# AST1060 register map
File version: 1.0
CPU: CM4 r0p1, little endian, MPU, FPU, 4 interrupt priority bits, 256 interrupts
Registers are 32-bit, read-write, reset 0x0 unless marked. A register's access mark holds for its fields unless they carry their own. Offsets are from the block's base; [hi:lo] are bit positions.

## gpio
Base 0x7E780000
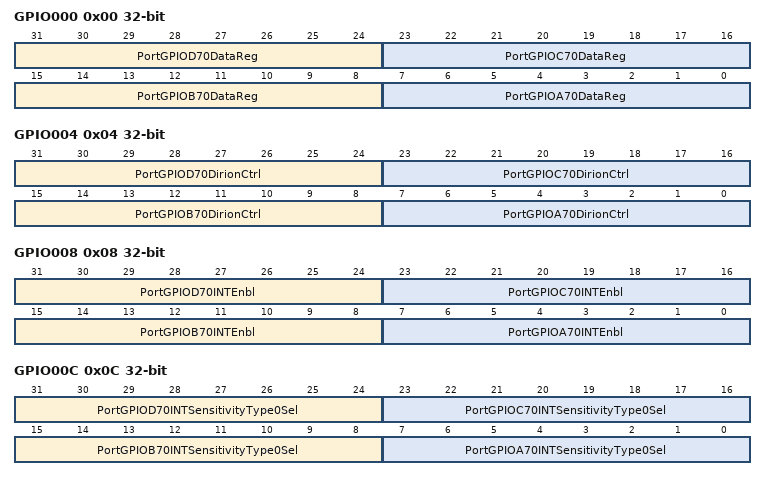
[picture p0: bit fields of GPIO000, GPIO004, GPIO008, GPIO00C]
0x00 GPIO000 — GPIO\_A/B/C/D Data Value Register
  [31:24] PortGPIOD70DataReg — Port GPIOD[7:0] data register
  [23:16] PortGPIOC70DataReg — Port GPIOC[7:0] data register
  [15:8] PortGPIOB70DataReg — Port GPIOB[7:0] data register
  [7:0] PortGPIOA70DataReg — Port GPIOA[7:0] data register
0x04 GPIO004 — GPIO\_A/B/C/D Direction Register
  [31:24] PortGPIOD70DirionCtrl — Port GPIOD[7:0] direction control
  [23:16] PortGPIOC70DirionCtrl — Port GPIOC[7:0] direction control
  [15:8] PortGPIOB70DirionCtrl — Port GPIOB[7:0] direction control
  [7:0] PortGPIOA70DirionCtrl — Port GPIOA[7:0] direction control
0x08 GPIO008 — GPIO\_A/B/C/D Interrupt Enable Register
  [31:24] PortGPIOD70INTEnbl — Port GPIOD[7:0] interrupt enable
  [23:16] PortGPIOC70INTEnbl — Port GPIOC[7:0] interrupt enable
  [15:8] PortGPIOB70INTEnbl — Port GPIOB[7:0] interrupt enable
  [7:0] PortGPIOA70INTEnbl — Port GPIOA[7:0] interrupt enable
0x0C GPIO00C — GPIO\_A/B/C/D Interrupt Sensitivity Type 0 Register
  [31:24] PortGPIOD70INTSensitivityType0Sel — Port GPIOD[7:0] interrupt sensitivity type 0 selection
  [23:16] PortGPIOC70INTSensitivityType0Sel — Port GPIOC[7:0] interrupt sensitivity type 0 selection
  [15:8] PortGPIOB70INTSensitivityType0Sel — Port GPIOB[7:0] interrupt sensitivity type 0 selection
  [7:0] PortGPIOA70INTSensitivityType0Sel — Port GPIOA[7:0] interrupt sensitivity type 0 selection
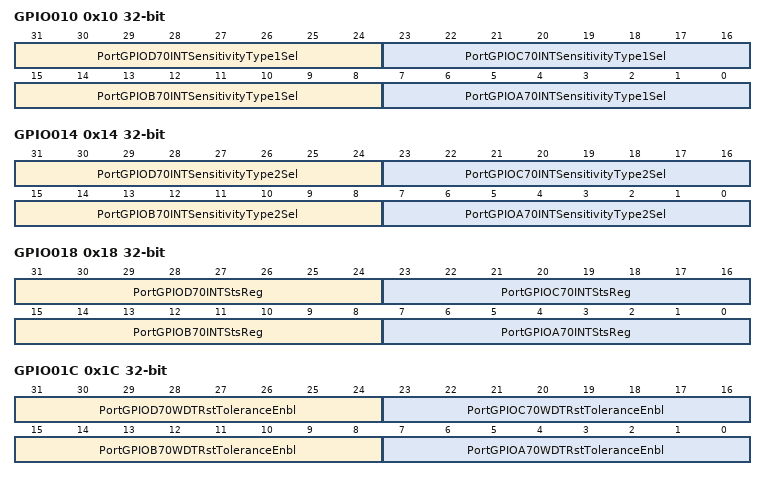
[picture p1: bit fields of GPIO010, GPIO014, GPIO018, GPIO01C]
0x10 GPIO010 — GPIO\_A/B/C/D Interrupt Sensitivity Type 1 Register
  [31:24] PortGPIOD70INTSensitivityType1Sel — Port GPIOD[7:0] interrupt sensitivity type 1 selection
  [23:16] PortGPIOC70INTSensitivityType1Sel — Port GPIOC[7:0] interrupt sensitivity type 1 selection
  [15:8] PortGPIOB70INTSensitivityType1Sel — Port GPIOB[7:0] interrupt sensitivity type 1 selection
  [7:0] PortGPIOA70INTSensitivityType1Sel — Port GPIOA[7:0] interrupt sensitivity type 1 selection
0x14 GPIO014 — GPIO\_A/B/C/D Interrupt Sensitivity Type 2 Register
  [31:24] PortGPIOD70INTSensitivityType2Sel — Port GPIOD[7:0] interrupt sensitivity type 2 selection
  [23:16] PortGPIOC70INTSensitivityType2Sel — Port GPIOC[7:0] interrupt sensitivity type 2 selection
  [15:8] PortGPIOB70INTSensitivityType2Sel — Port GPIOB[7:0] interrupt sensitivity type 2 selection
  [7:0] PortGPIOA70INTSensitivityType2Sel — Port GPIOA[7:0] interrupt sensitivity type 2 selection
0x18 GPIO018 — GPIO\_A/B/C/D Interrupt Status Register
  [31:24] PortGPIOD70INTStsReg — Port GPIOD[7:0] interrupt status register
  [23:16] PortGPIOC70INTStsReg — Port GPIOC[7:0] interrupt status register
  [15:8] PortGPIOB70INTStsReg — Port GPIOB[7:0] interrupt status register
  [7:0] PortGPIOA70INTStsReg — Port GPIOA[7:0] interrupt status register
0x1C GPIO01C — GPIO\_A/B/C/D Reset Tolerant Register
  [31:24] PortGPIOD70WDTRstToleranceEnbl — Port GPIOD[7:0] WDT reset tolerance enable
  [23:16] PortGPIOC70WDTRstToleranceEnbl — Port GPIOC[7:0] WDT reset tolerance enable
  [15:8] PortGPIOB70WDTRstToleranceEnbl — Port GPIOB[7:0] WDT reset tolerance enable
  [7:0] PortGPIOA70WDTRstToleranceEnbl — Port GPIOA[7:0] WDT reset tolerance enable
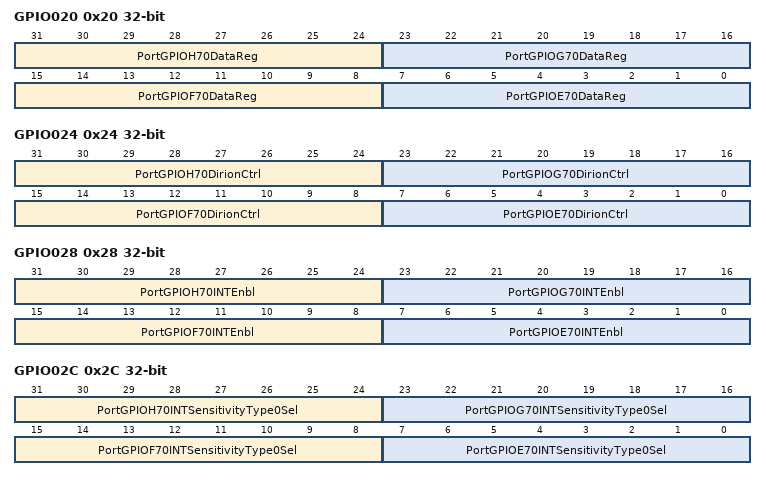
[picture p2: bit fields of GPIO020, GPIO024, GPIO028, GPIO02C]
0x20 GPIO020 — GPIO\_E/F/G/H Data Value Register
  [31:24] PortGPIOH70DataReg — Port GPIOH[7:0] data register
  [23:16] PortGPIOG70DataReg — Port GPIOG[7:0] data register
  [15:8] PortGPIOF70DataReg — Port GPIOF[7:0] data register
  [7:0] PortGPIOE70DataReg — Port GPIOE[7:0] data register
0x24 GPIO024 — GPIO\_E/F/G/H Direction Register
  [31:24] PortGPIOH70DirionCtrl — Port GPIOH[7:0] direction control
  [23:16] PortGPIOG70DirionCtrl — Port GPIOG[7:0] direction control
  [15:8] PortGPIOF70DirionCtrl — Port GPIOF[7:0] direction control
  [7:0] PortGPIOE70DirionCtrl — Port GPIOE[7:0] direction control
0x28 GPIO028 — GPIO\_E/F/G/H Interrupt Enable Register
  [31:24] PortGPIOH70INTEnbl — Port GPIOH[7:0] interrupt enable
  [23:16] PortGPIOG70INTEnbl — Port GPIOG[7:0] interrupt enable
  [15:8] PortGPIOF70INTEnbl — Port GPIOF[7:0] interrupt enable
  [7:0] PortGPIOE70INTEnbl — Port GPIOE[7:0] interrupt enable
0x2C GPIO02C — GPIO\_E/F/G/H Interrupt Sensitivity Type 0 Register
  [31:24] PortGPIOH70INTSensitivityType0Sel — Port GPIOH[7:0] interrupt sensitivity type 0 selection
  [23:16] PortGPIOG70INTSensitivityType0Sel — Port GPIOG[7:0] interrupt sensitivity type 0 selection
  [15:8] PortGPIOF70INTSensitivityType0Sel — Port GPIOF[7:0] interrupt sensitivity type 0 selection
  [7:0] PortGPIOE70INTSensitivityType0Sel — Port GPIOE[7:0] interrupt sensitivity type 0 selection
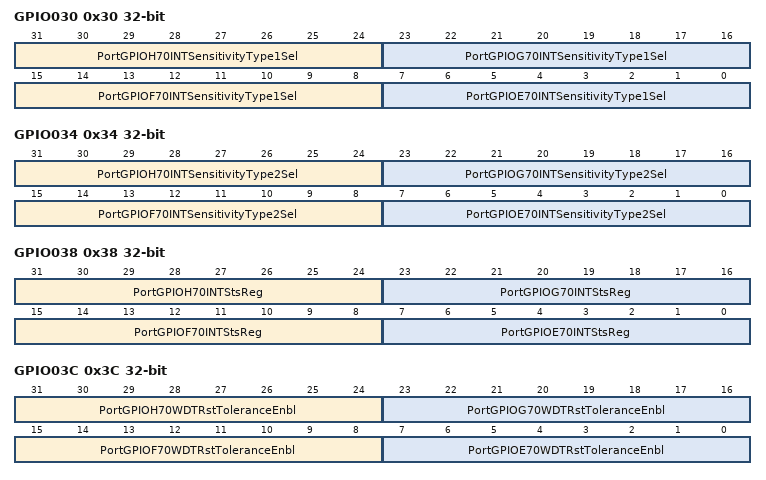
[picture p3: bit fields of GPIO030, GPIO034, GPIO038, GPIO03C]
0x30 GPIO030 — GPIO\_E/F/G/H Interrupt Sensitivity Type 1 Register
  [31:24] PortGPIOH70INTSensitivityType1Sel — Port GPIOH[7:0] interrupt sensitivity type 1 selection
  [23:16] PortGPIOG70INTSensitivityType1Sel — Port GPIOG[7:0] interrupt sensitivity type 1 selection
  [15:8] PortGPIOF70INTSensitivityType1Sel — Port GPIOF[7:0] interrupt sensitivity type 1 selection
  [7:0] PortGPIOE70INTSensitivityType1Sel — Port GPIOE[7:0] interrupt sensitivity type 1 selection
0x34 GPIO034 — GPIO\_E/F/G/H Interrupt Sensitivity Type 2 Register
  [31:24] PortGPIOH70INTSensitivityType2Sel — Port GPIOH[7:0] interrupt sensitivity type 2 selection
  [23:16] PortGPIOG70INTSensitivityType2Sel — Port GPIOG[7:0] interrupt sensitivity type 2 selection
  [15:8] PortGPIOF70INTSensitivityType2Sel — Port GPIOF[7:0] interrupt sensitivity type 2 selection
  [7:0] PortGPIOE70INTSensitivityType2Sel — Port GPIOE[7:0] interrupt sensitivity type 2 selection
0x38 GPIO038 — GPIO\_E/F/G/H Interrupt Status Register
  [31:24] PortGPIOH70INTStsReg — Port GPIOH[7:0] interrupt status register
  [23:16] PortGPIOG70INTStsReg — Port GPIOG[7:0] interrupt status register
  [15:8] PortGPIOF70INTStsReg — Port GPIOF[7:0] interrupt status register
  [7:0] PortGPIOE70INTStsReg — Port GPIOE[7:0] interrupt status register
0x3C GPIO03C — GPIO\_E/F/G/H Reset Tolerant Register
  [31:24] PortGPIOH70WDTRstToleranceEnbl — Port GPIOH[7:0] WDT reset tolerance enable
  [23:16] PortGPIOG70WDTRstToleranceEnbl — Port GPIOG[7:0] WDT reset tolerance enable
  [15:8] PortGPIOF70WDTRstToleranceEnbl — Port GPIOF[7:0] WDT reset tolerance enable
  [7:0] PortGPIOE70WDTRstToleranceEnbl — Port GPIOE[7:0] WDT reset tolerance enable
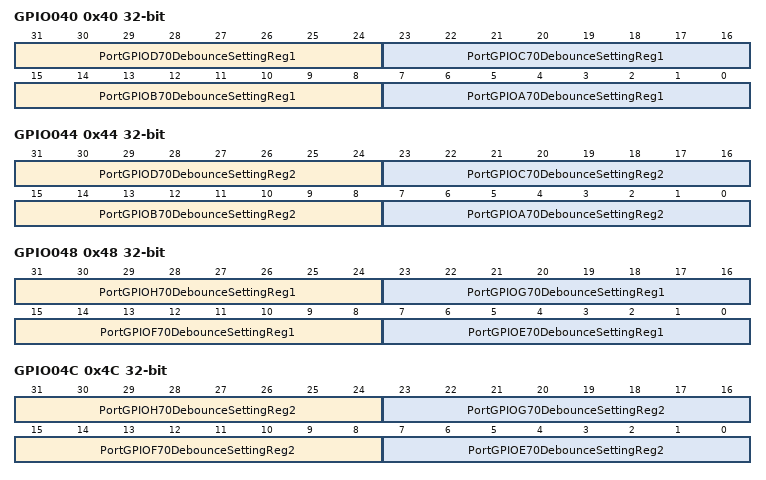
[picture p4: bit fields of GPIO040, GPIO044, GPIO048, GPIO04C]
0x40 GPIO040 — GPIO\_A/B/C/D Debounce Setting Register \#1
  [31:24] PortGPIOD70DebounceSettingReg1 — Port GPIOD[7:0] debounce setting register #1
  [23:16] PortGPIOC70DebounceSettingReg1 — Port GPIOC[7:0] debounce setting register #1
  [15:8] PortGPIOB70DebounceSettingReg1 — Port GPIOB[7:0] debounce setting register #1
  [7:0] PortGPIOA70DebounceSettingReg1 — Port GPIOA[7:0] debounce setting register #1
0x44 GPIO044 — GPIO\_A/B/C/D Debounce Setting Register \#2
  [31:24] PortGPIOD70DebounceSettingReg2 — Port GPIOD[7:0] debounce setting register #2
  [23:16] PortGPIOC70DebounceSettingReg2 — Port GPIOC[7:0] debounce setting register #2
  [15:8] PortGPIOB70DebounceSettingReg2 — Port GPIOB[7:0] debounce setting register #2
  [7:0] PortGPIOA70DebounceSettingReg2 — Port GPIOA[7:0] debounce setting register #2
0x48 GPIO048 — GPIO\_E/F/G/H Debounce Setting Register \#1
  [31:24] PortGPIOH70DebounceSettingReg1 — Port GPIOH[7:0] debounce setting register #1
  [23:16] PortGPIOG70DebounceSettingReg1 — Port GPIOG[7:0] debounce setting register #1
  [15:8] PortGPIOF70DebounceSettingReg1 — Port GPIOF[7:0] debounce setting register #1
  [7:0] PortGPIOE70DebounceSettingReg1 — Port GPIOE[7:0] debounce setting register #1
0x4C GPIO04C — GPIO\_E/F/G/H Debounce Setting Register \#2
  [31:24] PortGPIOH70DebounceSettingReg2 — Port GPIOH[7:0] debounce setting register #2
  [23:16] PortGPIOG70DebounceSettingReg2 — Port GPIOG[7:0] debounce setting register #2
  [15:8] PortGPIOF70DebounceSettingReg2 — Port GPIOF[7:0] debounce setting register #2
  [7:0] PortGPIOE70DebounceSettingReg2 — Port GPIOE[7:0] debounce setting register #2
0x50 GPIO050 — Debounce Timer Setting Register \#1
  [23:0] DebounceTimerValue
0x54 GPIO054 — Debounce Timer Setting Register \#2
  [23:0] DebounceTimerValue1 — Debounce Timer Value
0x58 GPIO058 — Debounce Timer Setting Register \#3
  [23:0] DebounceTimerValue2 — Debounce Timer Value
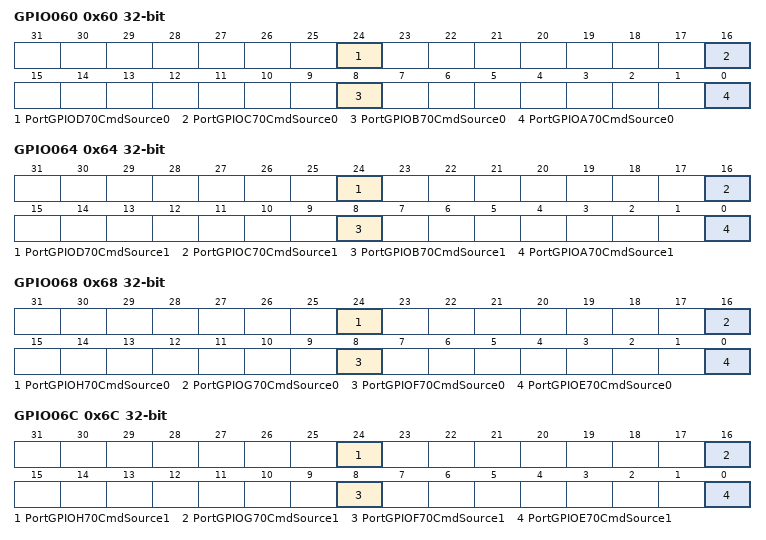
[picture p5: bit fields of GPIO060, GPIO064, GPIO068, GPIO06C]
0x60 GPIO060 — GPIO\_A/B/C/D Command Source 0
  [24] PortGPIOD70CmdSource0 — Port GPIOD[7:0] Command Source 0
  [16] PortGPIOC70CmdSource0 — Port GPIOC[7:0] Command Source 0
  [8] PortGPIOB70CmdSource0 — Port GPIOB[7:0] Command Source 0
  [0] PortGPIOA70CmdSource0 — Port GPIOA[7:0] Command Source 0
0x64 GPIO064 — GPIO\_A/B/C/D Command Source 1
  [24] PortGPIOD70CmdSource1 — Port GPIOD[7:0] Command Source 1
  [16] PortGPIOC70CmdSource1 — Port GPIOC[7:0] Command Source 1
  [8] PortGPIOB70CmdSource1 — Port GPIOB[7:0] Command Source 1
  [0] PortGPIOA70CmdSource1 — Port GPIOA[7:0] Command Source 1
0x68 GPIO068 — GPIO\_E/F/G/H Command Source 0
  [24] PortGPIOH70CmdSource0 — Port GPIOH[7:0] Command Source 0
  [16] PortGPIOG70CmdSource0 — Port GPIOG[7:0] Command Source 0
  [8] PortGPIOF70CmdSource0 — Port GPIOF[7:0] Command Source 0
  [0] PortGPIOE70CmdSource0 — Port GPIOE[7:0] Command Source 0
0x6C GPIO06C — GPIO\_E/F/G/H Command Source 1
  [24] PortGPIOH70CmdSource1 — Port GPIOH[7:0] Command Source 1
  [16] PortGPIOG70CmdSource1 — Port GPIOG[7:0] Command Source 1
  [8] PortGPIOF70CmdSource1 — Port GPIOF[7:0] Command Source 1
  [0] PortGPIOE70CmdSource1 — Port GPIOE[7:0] Command Source 1
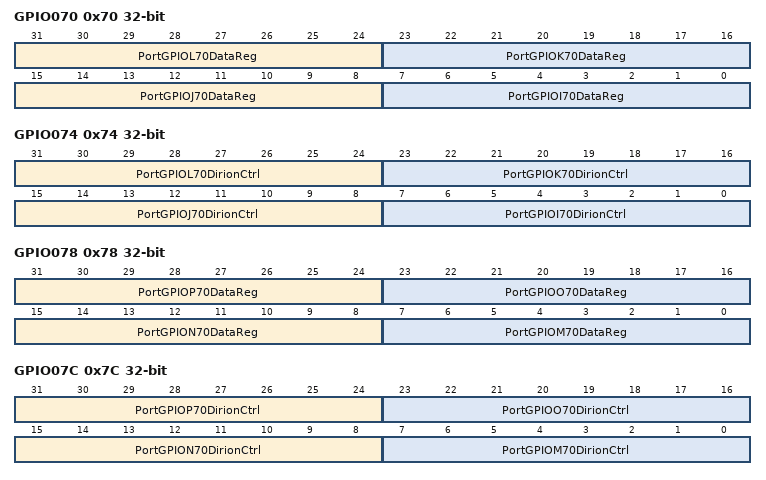
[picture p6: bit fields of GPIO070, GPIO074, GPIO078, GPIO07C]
0x70 GPIO070 — GPIO\_I/J/K/L Data Value Register
  [31:24] PortGPIOL70DataReg — Port GPIOL[7:0] data register
  [23:16] PortGPIOK70DataReg — Port GPIOK[7:0] data register
  [15:8] PortGPIOJ70DataReg — Port GPIOJ[7:0] data register
  [7:0] PortGPIOI70DataReg — Port GPIOI[7:0] data register
0x74 GPIO074 — GPIO\_I/J/K/L Direction Register
  [31:24] PortGPIOL70DirionCtrl — Port GPIOL[7:0] direction control
  [23:16] PortGPIOK70DirionCtrl — Port GPIOK[7:0] direction control
  [15:8] PortGPIOJ70DirionCtrl — Port GPIOJ[7:0] direction control
  [7:0] PortGPIOI70DirionCtrl — Port GPIOI[7:0] direction control
0x78 GPIO078 — GPIO\_M/N/O/P Data Value Register
  [31:24] PortGPIOP70DataReg — Port GPIOP[7:0] data register
  [23:16] PortGPIOO70DataReg — Port GPIOO[7:0] data register
  [15:8] PortGPION70DataReg — Port GPION[7:0] data register
  [7:0] PortGPIOM70DataReg — Port GPIOM[7:0] data register
0x7C GPIO07C — GPIO\_M/N/O/P Direction Register
  [31:24] PortGPIOP70DirionCtrl — Port GPIOP[7:0] direction control
  [23:16] PortGPIOO70DirionCtrl — Port GPIOO[7:0] direction control
  [15:8] PortGPION70DirionCtrl — Port GPION[7:0] direction control
  [7:0] PortGPIOM70DirionCtrl — Port GPIOM[7:0] direction control
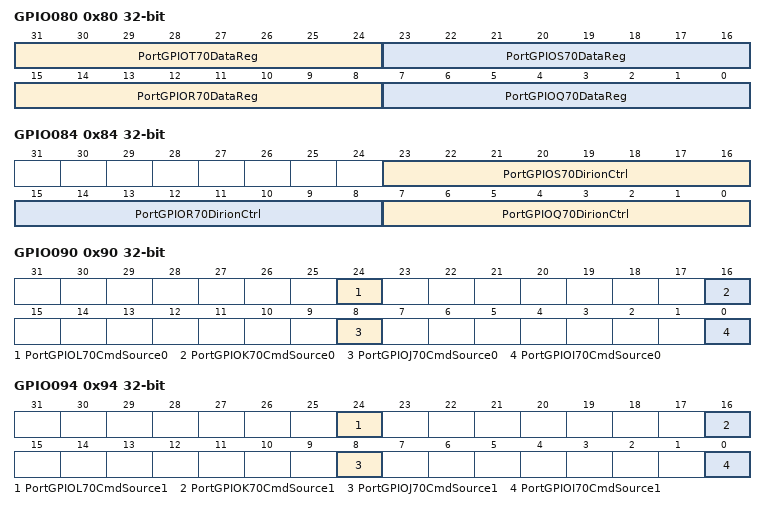
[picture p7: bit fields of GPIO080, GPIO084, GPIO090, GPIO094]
0x80 GPIO080 — GPIO\_Q/R/S/T Data Value Register
  [31:24] PortGPIOT70DataReg ro — Port GPIOT[7:0] data register
  [23:16] PortGPIOS70DataReg — Port GPIOS[7:0] data register
  [15:8] PortGPIOR70DataReg — Port GPIOR[7:0] data register
  [7:0] PortGPIOQ70DataReg — Port GPIOQ[7:0] data register
0x84 GPIO084 — GPIO\_Q/R/S/T Direction Register
  [23:16] PortGPIOS70DirionCtrl — Port GPIOS[7:0] direction control
  [15:8] PortGPIOR70DirionCtrl — Port GPIOR[7:0] direction control
  [7:0] PortGPIOQ70DirionCtrl — Port GPIOQ[7:0] direction control
0x88 GPIO088 — GPIO\_U Data Value Register
  [7:0] PortGPIU70DataReg ro — Port GPIU[7:0] data register
0x8C GPIO08C reset not defined — GPIO\_U Direction Register
0x90 GPIO090 — GPIO\_I/J/K/L Command Source 0
  [24] PortGPIOL70CmdSource0 — Port GPIOL[7:0] Command Source 0
  [16] PortGPIOK70CmdSource0 — Port GPIOK[7:0] Command Source 0
  [8] PortGPIOJ70CmdSource0 — Port GPIOJ[7:0] Command Source 0
  [0] PortGPIOI70CmdSource0 — Port GPIOI[7:0] Command Source 0
0x94 GPIO094 — GPIO\_I/J/K/L Command Source 1
  [24] PortGPIOL70CmdSource1 — Port GPIOL[7:0] Command Source 1
  [16] PortGPIOK70CmdSource1 — Port GPIOK[7:0] Command Source 1
  [8] PortGPIOJ70CmdSource1 — Port GPIOJ[7:0] Command Source 1
  [0] PortGPIOI70CmdSource1 — Port GPIOI[7:0] Command Source 1
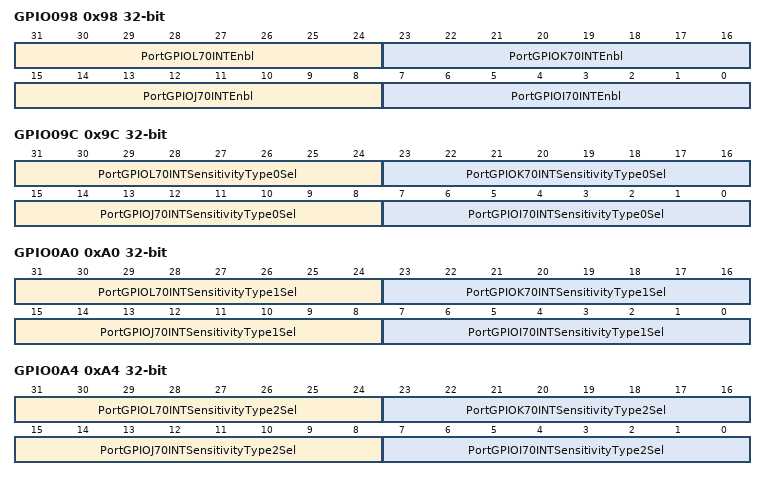
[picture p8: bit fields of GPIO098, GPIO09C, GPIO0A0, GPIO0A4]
0x98 GPIO098 — GPIO\_I/J/K/L Interrupt Enable Register
  [31:24] PortGPIOL70INTEnbl — Port GPIOL[7:0] interrupt enable
  [23:16] PortGPIOK70INTEnbl — Port GPIOK[7:0] interrupt enable
  [15:8] PortGPIOJ70INTEnbl — Port GPIOJ[7:0] interrupt enable
  [7:0] PortGPIOI70INTEnbl — Port GPIOI[7:0] interrupt enable
0x9C GPIO09C — GPIO\_I/J/K/L Interrupt Sensitivity Type 0 Register
  [31:24] PortGPIOL70INTSensitivityType0Sel — Port GPIOL[7:0] interrupt sensitivity type 0 selection
  [23:16] PortGPIOK70INTSensitivityType0Sel — Port GPIOK[7:0] interrupt sensitivity type 0 selection
  [15:8] PortGPIOJ70INTSensitivityType0Sel — Port GPIOJ[7:0] interrupt sensitivity type 0 selection
  [7:0] PortGPIOI70INTSensitivityType0Sel — Port GPIOI[7:0] interrupt sensitivity type 0 selection
0xA0 GPIO0A0 — GPIO\_I/J/K/L Interrupt Sensitivity Type 1 Register
  [31:24] PortGPIOL70INTSensitivityType1Sel — Port GPIOL[7:0] interrupt sensitivity type 1 selection
  [23:16] PortGPIOK70INTSensitivityType1Sel — Port GPIOK[7:0] interrupt sensitivity type 1 selection
  [15:8] PortGPIOJ70INTSensitivityType1Sel — Port GPIOJ[7:0] interrupt sensitivity type 1 selection
  [7:0] PortGPIOI70INTSensitivityType1Sel — Port GPIOI[7:0] interrupt sensitivity type 1 selection
0xA4 GPIO0A4 — GPIO\_I/J/K/L Interrupt Sensitivity Type 2 Register
  [31:24] PortGPIOL70INTSensitivityType2Sel — Port GPIOL[7:0] interrupt sensitivity type 2 selection
  [23:16] PortGPIOK70INTSensitivityType2Sel — Port GPIOK[7:0] interrupt sensitivity type 2 selection
  [15:8] PortGPIOJ70INTSensitivityType2Sel — Port GPIOJ[7:0] interrupt sensitivity type 2 selection
  [7:0] PortGPIOI70INTSensitivityType2Sel — Port GPIOI[7:0] interrupt sensitivity type 2 selection
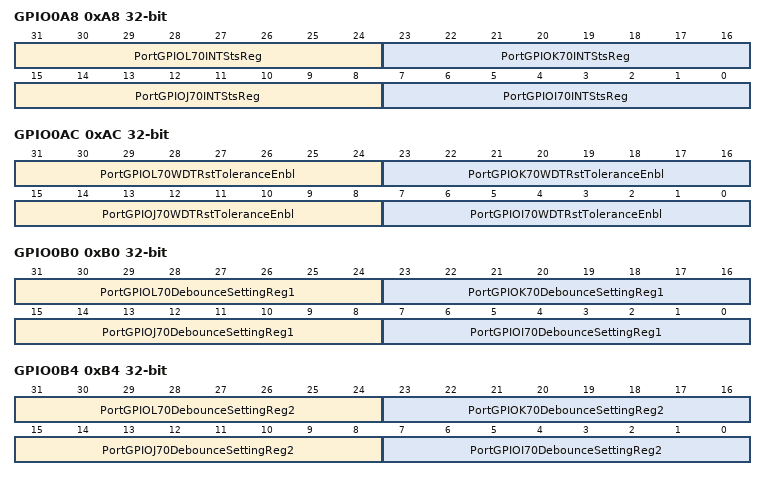
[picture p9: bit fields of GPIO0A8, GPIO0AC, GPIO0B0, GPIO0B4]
0xA8 GPIO0A8 — GPIO\_I/J/K/L Interrupt Status Register
  [31:24] PortGPIOL70INTStsReg — Port GPIOL[7:0] interrupt status register
  [23:16] PortGPIOK70INTStsReg — Port GPIOK[7:0] interrupt status register
  [15:8] PortGPIOJ70INTStsReg — Port GPIOJ[7:0] interrupt status register
  [7:0] PortGPIOI70INTStsReg — Port GPIOI[7:0] interrupt status register
0xAC GPIO0AC — GPIO\_I/J/K/L Reset Tolerant Register
  [31:24] PortGPIOL70WDTRstToleranceEnbl — Port GPIOL[7:0] WDT reset tolerance enable
  [23:16] PortGPIOK70WDTRstToleranceEnbl — Port GPIOK[7:0] WDT reset tolerance enable
  [15:8] PortGPIOJ70WDTRstToleranceEnbl — Port GPIOJ[7:0] WDT reset tolerance enable
  [7:0] PortGPIOI70WDTRstToleranceEnbl — Port GPIOI[7:0] WDT reset tolerance enable
0xB0 GPIO0B0 — GPIO\_I/J/K/L Debounce Setting Register \#1
  [31:24] PortGPIOL70DebounceSettingReg1 — Port GPIOL[7:0] debounce setting register #1
  [23:16] PortGPIOK70DebounceSettingReg1 — Port GPIOK[7:0] debounce setting register #1
  [15:8] PortGPIOJ70DebounceSettingReg1 — Port GPIOJ[7:0] debounce setting register #1
  [7:0] PortGPIOI70DebounceSettingReg1 — Port GPIOI[7:0] debounce setting register #1
0xB4 GPIO0B4 — GPIO\_I/J/K/L Debounce Setting Register \#2
  [31:24] PortGPIOL70DebounceSettingReg2 — Port GPIOL[7:0] debounce setting register #2
  [23:16] PortGPIOK70DebounceSettingReg2 — Port GPIOK[7:0] debounce setting register #2
  [15:8] PortGPIOJ70DebounceSettingReg2 — Port GPIOJ[7:0] debounce setting register #2
  [7:0] PortGPIOI70DebounceSettingReg2 — Port GPIOI[7:0] debounce setting register #2
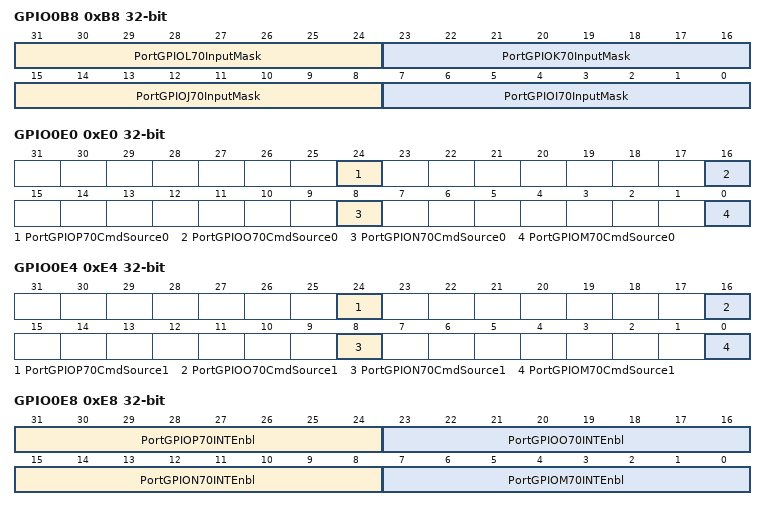
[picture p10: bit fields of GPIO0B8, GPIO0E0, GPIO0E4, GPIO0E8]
0xB8 GPIO0B8 — GPIO\_I/J/K/L Input Mask Register
  [31:24] PortGPIOL70InputMask, [23:16] PortGPIOK70InputMask, [15:8] PortGPIOJ70InputMask, [7:0] PortGPIOI70InputMask
0xC0 GPIO0C0 — GPIO\_A/B/C/D Data Read Register
  [31:0] DataWrittenToGPIO000GPIODGPIOCGPIOBGPIOA ro
0xC4 GPIO0C4 — GPIO\_E/F/G/H Data Read Register
  [31:0] DataWrittenToGPIO020GPIOHGPIOGGPIOFGPIOE ro
0xC8 GPIO0C8 — GPIO\_I/J/K/L Data Read Register
  [31:0] DataWrittenToGPIO070GPIOLGPIOKGPIOJGPIOI ro
0xCC GPIO0CC — GPIO\_M/N/O/P Data Read Register
  [31:0] DataWrittenToGPIO078GPIOPGPIOOGPIONGPIOM ro
0xD0 GPIO0D0 — GPIO\_Q/R/S/T Data Read Register
  [31:0] DataWrittenToGPIO080GPIOTGPIOSGPIORGPIOQ ro
0xD4 GPIO0D4 — GPIO\_U Data Read Register
  [7:0] DataWrittenToGPIO088GPIU ro
0xE0 GPIO0E0 — GPIO\_M/N/O/P Command Source 0
  [24] PortGPIOP70CmdSource0 — Port GPIOP[7:0] Command Source 0
  [16] PortGPIOO70CmdSource0 — Port GPIOO[7:0] Command Source 0
  [8] PortGPION70CmdSource0 — Port GPION[7:0] Command Source 0
  [0] PortGPIOM70CmdSource0 — Port GPIOM[7:0] Command Source 0
0xE4 GPIO0E4 — GPIO\_M/N/O/P Command Source 1
  [24] PortGPIOP70CmdSource1 — Port GPIOP[7:0] Command Source 1
  [16] PortGPIOO70CmdSource1 — Port GPIOO[7:0] Command Source 1
  [8] PortGPION70CmdSource1 — Port GPION[7:0] Command Source 1
  [0] PortGPIOM70CmdSource1 — Port GPIOM[7:0] Command Source 1
0xE8 GPIO0E8 — GPIO\_M/N/O/P Interrupt Enable Register
  [31:24] PortGPIOP70INTEnbl — Port GPIOP[7:0] interrupt enable
  [23:16] PortGPIOO70INTEnbl — Port GPIOO[7:0] interrupt enable
  [15:8] PortGPION70INTEnbl — Port GPION[7:0] interrupt enable
  [7:0] PortGPIOM70INTEnbl — Port GPIOM[7:0] interrupt enable
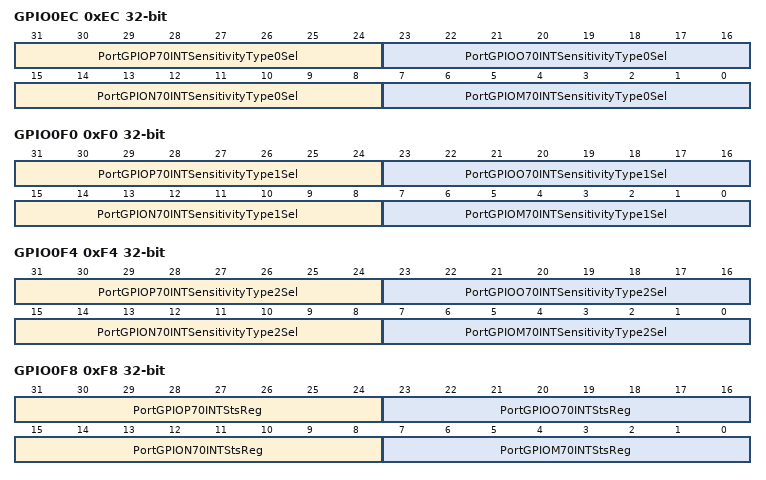
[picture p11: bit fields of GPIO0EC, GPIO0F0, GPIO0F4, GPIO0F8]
0xEC GPIO0EC — GPIO\_M/N/O/P Interrupt Sensitivity Type 0 Register
  [31:24] PortGPIOP70INTSensitivityType0Sel — Port GPIOP[7:0] interrupt sensitivity type 0 selection
  [23:16] PortGPIOO70INTSensitivityType0Sel — Port GPIOO[7:0] interrupt sensitivity type 0 selection
  [15:8] PortGPION70INTSensitivityType0Sel — Port GPION[7:0] interrupt sensitivity type 0 selection
  [7:0] PortGPIOM70INTSensitivityType0Sel — Port GPIOM[7:0] interrupt sensitivity type 0 selection
0xF0 GPIO0F0 — GPIO\_M/N/O/P Interrupt Sensitivity Type 1 Register
  [31:24] PortGPIOP70INTSensitivityType1Sel — Port GPIOP[7:0] interrupt sensitivity type 1 selection
  [23:16] PortGPIOO70INTSensitivityType1Sel — Port GPIOO[7:0] interrupt sensitivity type 1 selection
  [15:8] PortGPION70INTSensitivityType1Sel — Port GPION[7:0] interrupt sensitivity type 1 selection
  [7:0] PortGPIOM70INTSensitivityType1Sel — Port GPIOM[7:0] interrupt sensitivity type 1 selection
0xF4 GPIO0F4 — GPIO\_M/N/O/P Interrupt Sensitivity Type 2 Register
  [31:24] PortGPIOP70INTSensitivityType2Sel — Port GPIOP[7:0] interrupt sensitivity type 2 selection
  [23:16] PortGPIOO70INTSensitivityType2Sel — Port GPIOO[7:0] interrupt sensitivity type 2 selection
  [15:8] PortGPION70INTSensitivityType2Sel — Port GPION[7:0] interrupt sensitivity type 2 selection
  [7:0] PortGPIOM70INTSensitivityType2Sel — Port GPIOM[7:0] interrupt sensitivity type 2 selection
0xF8 GPIO0F8 — GPIO\_M/N/O/P Interrupt Status Register
  [31:24] PortGPIOP70INTStsReg — Port GPIOP[7:0] interrupt status register
  [23:16] PortGPIOO70INTStsReg — Port GPIOO[7:0] interrupt status register
  [15:8] PortGPION70INTStsReg — Port GPION[7:0] interrupt status register
  [7:0] PortGPIOM70INTStsReg — Port GPIOM[7:0] interrupt status register
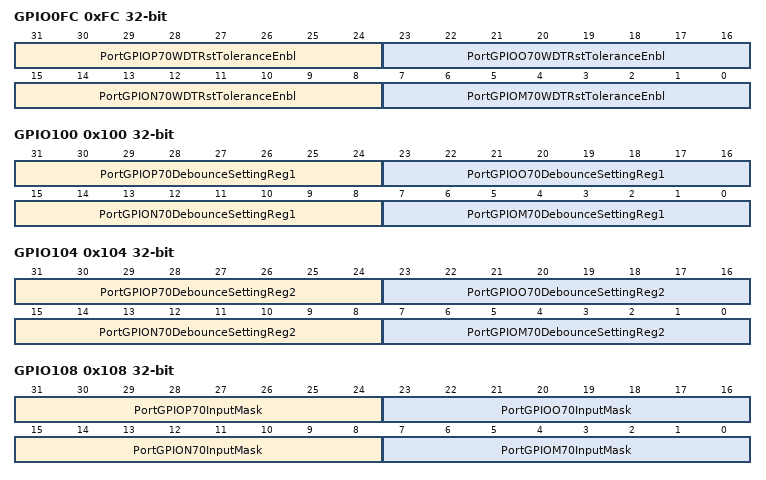
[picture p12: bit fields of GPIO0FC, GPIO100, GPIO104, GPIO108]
0xFC GPIO0FC — GPIO\_M/N/O/P Reset Tolerant Register
  [31:24] PortGPIOP70WDTRstToleranceEnbl — Port GPIOP[7:0] WDT reset tolerance enable
  [23:16] PortGPIOO70WDTRstToleranceEnbl — Port GPIOO[7:0] WDT reset tolerance enable
  [15:8] PortGPION70WDTRstToleranceEnbl — Port GPION[7:0] WDT reset tolerance enable
  [7:0] PortGPIOM70WDTRstToleranceEnbl — Port GPIOM[7:0] WDT reset tolerance enable
0x100 GPIO100 — GPIO\_M/N/O/P Debounce Setting Register \#1
  [31:24] PortGPIOP70DebounceSettingReg1 — Port GPIOP[7:0] debounce setting register #1
  [23:16] PortGPIOO70DebounceSettingReg1 — Port GPIOO[7:0] debounce setting register #1
  [15:8] PortGPION70DebounceSettingReg1 — Port GPION[7:0] debounce setting register #1
  [7:0] PortGPIOM70DebounceSettingReg1 — Port GPIOM[7:0] debounce setting register #1
0x104 GPIO104 — GPIO\_M/N/O/P Debounce Setting Register \#2
  [31:24] PortGPIOP70DebounceSettingReg2 — Port GPIOP[7:0] debounce setting register #2
  [23:16] PortGPIOO70DebounceSettingReg2 — Port GPIOO[7:0] debounce setting register #2
  [15:8] PortGPION70DebounceSettingReg2 — Port GPION[7:0] debounce setting register #2
  [7:0] PortGPIOM70DebounceSettingReg2 — Port GPIOM[7:0] debounce setting register #2
0x108 GPIO108 — GPIO\_M/N/O/P Input Mask Register
  [31:24] PortGPIOP70InputMask, [23:16] PortGPIOO70InputMask, [15:8] PortGPION70InputMask, [7:0] PortGPIOM70InputMask
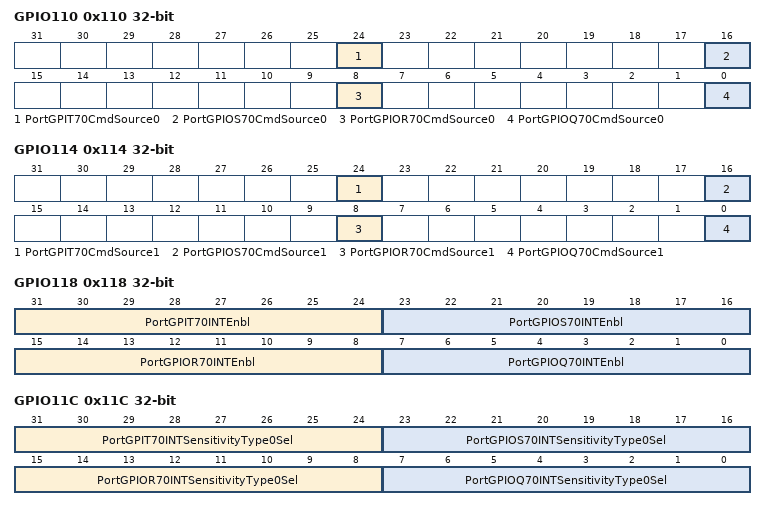
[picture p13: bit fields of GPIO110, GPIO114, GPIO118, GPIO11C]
0x110 GPIO110 — GPIO\_Q/R/S/T Command Source 0
  [24] PortGPIT70CmdSource0 — Port GPIT[7:0] Command Source 0
  [16] PortGPIOS70CmdSource0 — Port GPIOS[7:0] Command Source 0
  [8] PortGPIOR70CmdSource0 — Port GPIOR[7:0] Command Source 0
  [0] PortGPIOQ70CmdSource0 — Port GPIOQ[7:0] Command Source 0
0x114 GPIO114 — GPIO\_Q/R/S/T Command Source 1
  [24] PortGPIT70CmdSource1 — Port GPIT[7:0] Command Source 1
  [16] PortGPIOS70CmdSource1 — Port GPIOS[7:0] Command Source 1
  [8] PortGPIOR70CmdSource1 — Port GPIOR[7:0] Command Source 1
  [0] PortGPIOQ70CmdSource1 — Port GPIOQ[7:0] Command Source 1
0x118 GPIO118 — GPIO\_Q/R/S/T Interrupt Enable Register
  [31:24] PortGPIT70INTEnbl — Port GPIT[7:0] interrupt enable
  [23:16] PortGPIOS70INTEnbl — Port GPIOS[7:0] interrupt enable
  [15:8] PortGPIOR70INTEnbl — Port GPIOR[7:0] interrupt enable
  [7:0] PortGPIOQ70INTEnbl — Port GPIOQ[7:0] interrupt enable
0x11C GPIO11C — GPIO\_Q/R/S/T Interrupt Sensitivity Type 0 Register
  [31:24] PortGPIT70INTSensitivityType0Sel — Port GPIT[7:0] interrupt sensitivity type 0 selection
  [23:16] PortGPIOS70INTSensitivityType0Sel — Port GPIOS[7:0] interrupt sensitivity type 0 selection
  [15:8] PortGPIOR70INTSensitivityType0Sel — Port GPIOR[7:0] interrupt sensitivity type 0 selection
  [7:0] PortGPIOQ70INTSensitivityType0Sel — Port GPIOQ[7:0] interrupt sensitivity type 0 selection
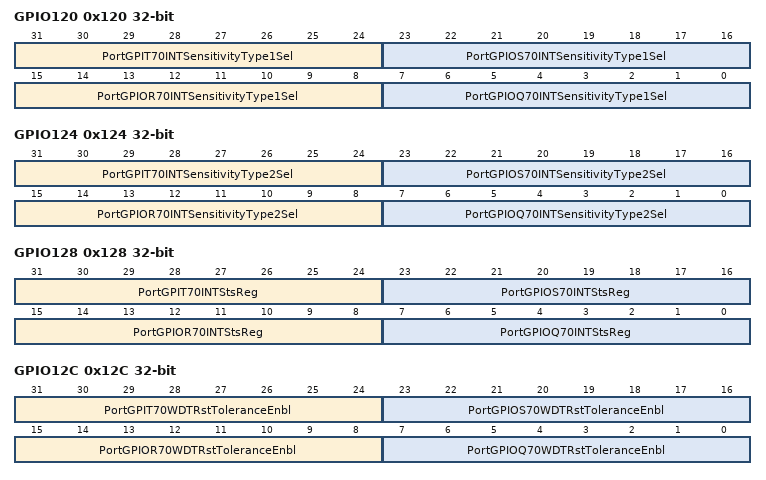
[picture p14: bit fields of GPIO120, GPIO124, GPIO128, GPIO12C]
0x120 GPIO120 — GPIO\_Q/R/S/T Interrupt Sensitivity Type 1 Register
  [31:24] PortGPIT70INTSensitivityType1Sel — Port GPIT[7:0] interrupt sensitivity type 1 selection
  [23:16] PortGPIOS70INTSensitivityType1Sel — Port GPIOS[7:0] interrupt sensitivity type 1 selection
  [15:8] PortGPIOR70INTSensitivityType1Sel — Port GPIOR[7:0] interrupt sensitivity type 1 selection
  [7:0] PortGPIOQ70INTSensitivityType1Sel — Port GPIOQ[7:0] interrupt sensitivity type 1 selection
0x124 GPIO124 — GPIO\_Q/R/S/T Interrupt Sensitivity Type 2 Register
  [31:24] PortGPIT70INTSensitivityType2Sel — Port GPIT[7:0] interrupt sensitivity type 2 selection
  [23:16] PortGPIOS70INTSensitivityType2Sel — Port GPIOS[7:0] interrupt sensitivity type 2 selection
  [15:8] PortGPIOR70INTSensitivityType2Sel — Port GPIOR[7:0] interrupt sensitivity type 2 selection
  [7:0] PortGPIOQ70INTSensitivityType2Sel — Port GPIOQ[7:0] interrupt sensitivity type 2 selection
0x128 GPIO128 — GPIO\_Q/R/S/T Interrupt Status Register
  [31:24] PortGPIT70INTStsReg — Port GPIT[7:0] interrupt status register
  [23:16] PortGPIOS70INTStsReg — Port GPIOS[7:0] interrupt status register
  [15:8] PortGPIOR70INTStsReg — Port GPIOR[7:0] interrupt status register
  [7:0] PortGPIOQ70INTStsReg — Port GPIOQ[7:0] interrupt status register
0x12C GPIO12C — GPIO\_Q/R/S/T Reset Tolerant Register
  [31:24] PortGPIT70WDTRstToleranceEnbl — Port GPIT[7:0] WDT reset tolerance enable
  [23:16] PortGPIOS70WDTRstToleranceEnbl — Port GPIOS[7:0] WDT reset tolerance enable
  [15:8] PortGPIOR70WDTRstToleranceEnbl — Port GPIOR[7:0] WDT reset tolerance enable
  [7:0] PortGPIOQ70WDTRstToleranceEnbl — Port GPIOQ[7:0] WDT reset tolerance enable
0x130 GPIO130 — GPIO\_Q/R/S/T Debounce Setting Register \#1
  [31:24] PortGPIT70DebounceSettingReg1 — Port GPIT[7:0] debounce setting register #1
  [23:16] PortGPIOS70DebounceSettingReg1 — Port GPIOS[7:0] debounce setting register #1
  [15:8] PortGPIOR70DebounceSettingReg1 — Port GPIOR[7:0] debounce setting register #1
  [7:0] PortGPIOQ70DebounceSettingReg1 — Port GPIOQ[7:0] debounce setting register #1
0x134 GPIO134 — GPIO\_Q/R/S/T Debounce Setting Register \#2
  [31:24] PortGPIT70DebounceSettingReg2 — Port GPIT[7:0] debounce setting register #2
  [23:16] PortGPIOS70DebounceSettingReg2 — Port GPIOS[7:0] debounce setting register #2
  [15:8] PortGPIOR70DebounceSettingReg2 — Port GPIOR[7:0] debounce setting register #2
  [7:0] PortGPIOQ70DebounceSettingReg2 — Port GPIOQ[7:0] debounce setting register #2
0x138 GPIO138 — GPIO\_Q/R/S/T Input Mask Register
  [31:24] PortGPIT70InputMask, [23:16] PortGPIOS70InputMask, [15:8] PortGPIOR70InputMask, [7:0] PortGPIOQ70InputMask
0x140 GPIO140 — GPIO\_U Command Source 0
  [0] PortGPIU70CmdSource0 — Port GPIU[7:0] Command Source 0
0x144 GPIO144 — GPIO\_U Command Source 1
  [0] PortGPIU70CmdSource1 — Port GPIU[7:0] Command Source 1
0x148 GPIO148 — GPIO\_U Interrupt Enable Register
  [7:0] PortGPIU70INTEnbl — Port GPIU[7:0] interrupt enable
0x14C GPIO14C — GPIO\_U Interrupt Sensitivity Type 0 Register
  [7:0] PortGPIU70INTSensitivityType0Sel — Port GPIU[7:0] interrupt sensitivity type 0 selection
0x150 GPIO150 — GPIO\_U Interrupt Sensitivity Type 1 Register
  [7:0] PortGPIU70INTSensitivityType1Sel — Port GPIU[7:0] interrupt sensitivity type 1 selection
0x154 GPIO154 — GPIO\_U Interrupt Sensitivity Type 2 Register
  [7:0] PortGPIU70INTSensitivityType2Sel — Port GPIU[7:0] interrupt sensitivity type 2 selection
0x158 GPIO158 — GPIO\_U Interrupt Status Register
  [7:0] PortGPIU70INTStsReg — Port GPIU[7:0] interrupt status register
0x15C GPIO15C — GPIO\_U Reset Tolerant Register
  [7:0] PortGPIU70WDTRstToleranceEnbl — Port GPIU[7:0] WDT reset tolerance enable
0x160 GPIO160 — GPIO\_U Debounce Setting Register \#1
  [7:0] PortGPIU70DebounceSettingReg1 — Port GPIU[7:0] debounce setting register #1
0x164 GPIO164 — GPIO\_U Debounce Setting Register \#2
  [7:0] PortGPIU70DebounceSettingReg2 — Port GPIU[7:0] debounce setting register #2
0x168 GPIO168 — GPIO\_U Input Mask Register
  [7:0] PortGPIU70InputMask
0x1D0 GPIO1D0 — GPIO\_A/B/C/D Input Mask Register
  [31:24] PortGPIOD70InputMask, [23:16] PortGPIOC70InputMask, [15:8] PortGPIOB70InputMask, [7:0] PortGPIOA70InputMask
0x1D4 GPIO1D4 — GPIO\_E/F/G/H Input Mask Register
  [31:24] PortGPIOH70InputMask, [23:16] PortGPIOG70InputMask, [15:8] PortGPIOF70InputMask, [7:0] PortGPIOE70InputMask
0x2AC GPIO2AC — GPIO Index Register
  [31:20] IndexData
  [19:16] IndexType
  [12] IndexCmd — Index Command
    0=Write; 1=Read
  [7:0] IndexNumber
0x500 GPIO500 — Serial GPIO\_A/B/C/D 1 Data Value Register
  [31:24] PortSerialGPIOD70DataReg — Port Serial GPIOD[7:0] data register
  [23:16] PortSerialGPIOC70DataReg — Port Serial GPIOC[7:0] data register
  [15:8] PortSerialGPIOB70DataReg — Port Serial GPIOB[7:0] data register
  [7:0] PortSerialGPIOA70DataReg — Port Serial GPIOA[7:0] data register
